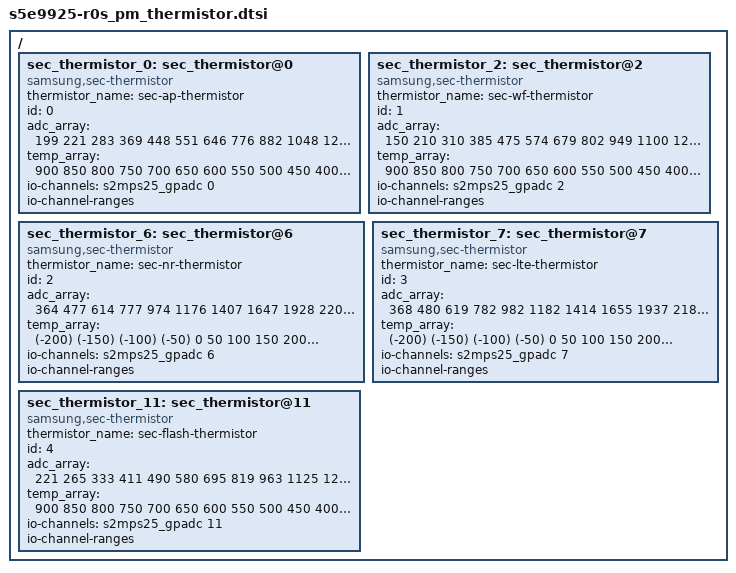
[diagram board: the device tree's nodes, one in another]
/*
 * SAMSUNG S5E9925 Power Management device tree source
 *
 * Copyright (c) 2021 Samsung Electronics Co., Ltd.
 *		http://www.samsung.com
 *
 * This program is free software; you can redistribute it and/or modify
 * it under the terms of the GNU General Public License version 2 as
 * published by the Free Software Foundation.
 */

/ {
	fragment@model {
		target-path = "/";
		__overlay__ {
			sec_thermistor_0: sec_thermistor@0 {
				compatible = "samsung,sec-thermistor";
				status = "okay";
				thermistor_name = "sec-ap-thermistor";
				id = <0>;

				adc_array = <199 221 283 369 448 551 646 776 882 1048
					1215 1403 1611 1850 2100 2360 2600 2840 3055 3257
					3423 3555 3673>;
				temp_array = <900 850 800 750 700 650 600 550 500 450
					  400 350 300 250 200 150 100 50 0 (-50)
					  (-100) (-150) (-200)>;

				io-channels = <&s2mps25_gpadc 0>;
				io-channel-names = "adc-ap-temp";
				io-channel-ranges;
			};

			sec_thermistor_2: sec_thermistor@2 {
				compatible = "samsung,sec-thermistor";
				status = "okay";
				thermistor_name = "sec-wf-thermistor";
				id = <1>;

				adc_array = <150 210 310 385 475 574 679 802 949 1100
					1250 1457 1668 1897 2161 2443 2683 2914 3114 3312
					3474 3610 3722>;
				temp_array = <900 850 800 750 700 650 600 550 500 450
					  400 350 300 250 200 150 100 50 0 (-50)
					  (-100) (-150) (-200)>;

				io-channels = <&s2mps25_gpadc 2>;
				io-channel-names = "adc-wf-temp";
				io-channel-ranges;
			};

			sec_thermistor_6: sec_thermistor@6 {
				compatible = "samsung,sec-thermistor";
				status = "okay";
				thermistor_name = "sec-nr-thermistor";
				id = <2>;

				adc_array = <364 477 614 777 974 1176 1407 1647 1928 2209
					2423 2636 2843 2977 3140 3286 3410 3515 3612 3693
					3770 3840 3860>;
				temp_array = <(-200) (-150) (-100) (-50) 0 50 100 150 200 250
					300 350 400 450 500 550 600 650 700 750
					800 850 900>;

				io-channels = <&s2mps25_gpadc 6>;
				io-channel-names = "adc-nr-temp";
				io-channel-ranges;
			};

			sec_thermistor_7: sec_thermistor@7 {
				compatible = "samsung,sec-thermistor";
				status = "okay";
				thermistor_name = "sec-lte-thermistor";
				id = <3>;

				adc_array = <368 480 619 782 982 1182 1414 1655 1937 2180
					2431 2641 2847 2983 3146 3291 3412 3518 3615 3694
					3760 3825 3860>;
				temp_array = <(-200) (-150) (-100) (-50) 0 50 100 150 200 250
					300 350 400 450 500 550 600 650 700 750
					800 850 900>;

				io-channels = <&s2mps25_gpadc 7>;
				io-channel-names = "adc-lte-temp";
				io-channel-ranges;
			};

			sec_thermistor_11: sec_thermistor@11 {
				compatible = "samsung,sec-thermistor";
				status = "okay";
				thermistor_name = "sec-flash-thermistor";
				id = <4>;

				adc_array = <221 265 333 411 490 580 695 819 963 1125
					1281 1483 1696 1929 2175 2439 2677 2905 3103 3290
					3450 3594 3691>;
				temp_array = <900 850 800 750 700 650 600 550 500 450
					  400 350 300 250 200 150 100 50 0 (-50)
					  (-100) (-150) (-200)>;

				io-channels = <&s2mps25_gpadc 11>;
				io-channel-names = "adc-flash-temp";
				io-channel-ranges;
			};
		}; /* end of __overlay__ */
	}; /* end of fragment */
}; /* end of root */
